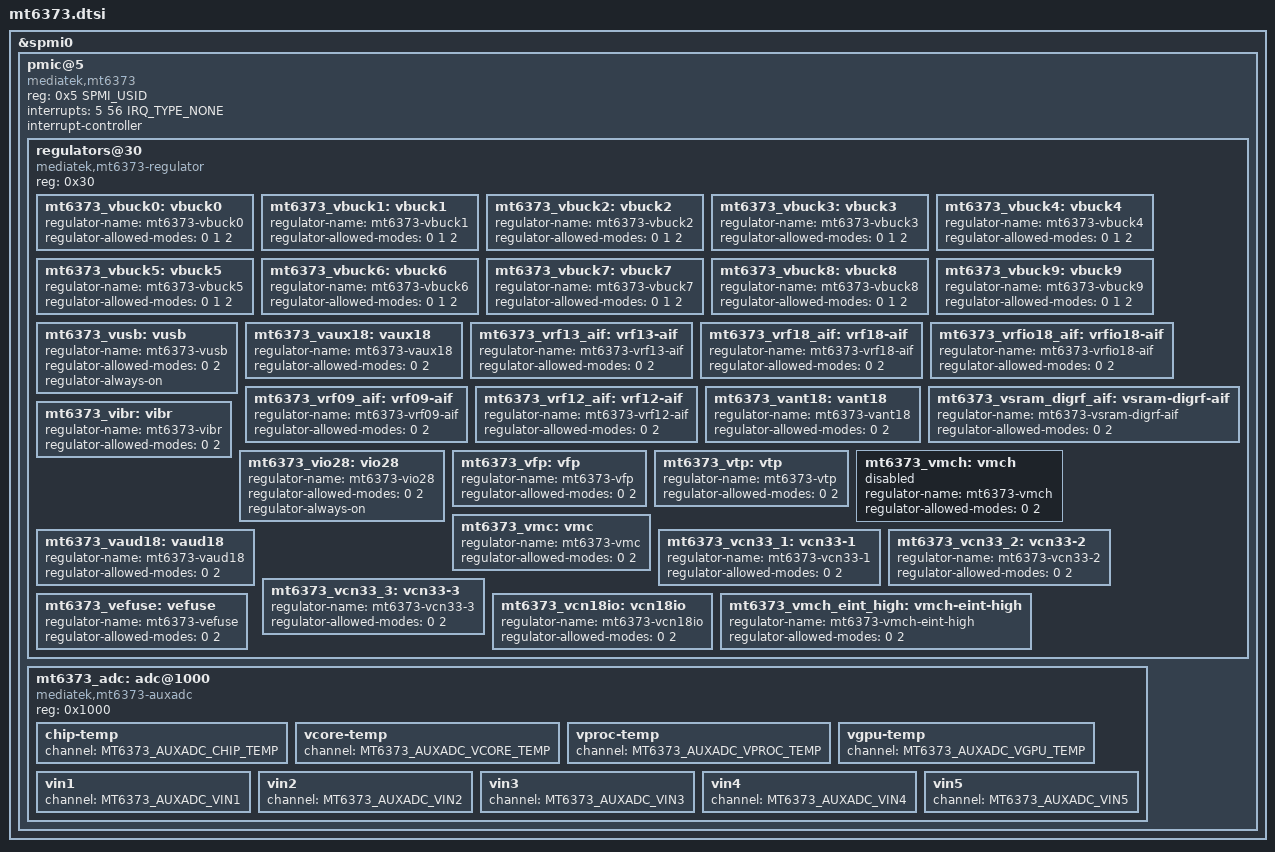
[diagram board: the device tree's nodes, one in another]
// SPDX-License-Identifier: (GPL-2.0 OR MIT)
/*
 * Copyright (c) 2023 MediaTek Inc.
 * Copyright (c) 2025 Collabora Ltd
 *                    AngeloGioacchino Del Regno <angelogioacchino.delregno@collabora.com>
 */
#include <dt-bindings/iio/adc/mediatek,mt6373-auxadc.h>
#include <dt-bindings/interrupt-controller/irq.h>
#include <dt-bindings/spmi/spmi.h>

&spmi0 {
	pmic@5 {
		compatible = "mediatek,mt6373";
		reg = <0x5 SPMI_USID>;
		interrupts = <5 56 IRQ_TYPE_NONE>;
		interrupt-controller;
		#address-cells = <1>;
		#interrupt-cells = <3>;
		#size-cells = <0>;

		regulators@30 {
			compatible = "mediatek,mt6373-regulator";
			reg = <0x30>;

			mt6373_vbuck0: vbuck0 {
				regulator-name = "mt6373-vbuck0";
				regulator-allowed-modes = <0 1 2>;
			};

			mt6373_vbuck1: vbuck1 {
				regulator-name = "mt6373-vbuck1";
				regulator-allowed-modes = <0 1 2>;
			};

			mt6373_vbuck2: vbuck2 {
				regulator-name = "mt6373-vbuck2";
				regulator-allowed-modes = <0 1 2>;
			};

			mt6373_vbuck3: vbuck3 {
				regulator-name = "mt6373-vbuck3";
				regulator-allowed-modes = <0 1 2>;
			};

			mt6373_vbuck4: vbuck4 {
				regulator-name = "mt6373-vbuck4";
				regulator-allowed-modes = <0 1 2>;
			};

			mt6373_vbuck5: vbuck5 {
				regulator-name = "mt6373-vbuck5";
				regulator-allowed-modes = <0 1 2>;
			};

			mt6373_vbuck6: vbuck6 {
				regulator-name = "mt6373-vbuck6";
				regulator-allowed-modes = <0 1 2>;
			};

			mt6373_vbuck7: vbuck7 {
				regulator-name = "mt6373-vbuck7";
				regulator-allowed-modes = <0 1 2>;
			};

			mt6373_vbuck8: vbuck8 {
				regulator-name = "mt6373-vbuck8";
				regulator-allowed-modes = <0 1 2>;
			};

			mt6373_vbuck9: vbuck9 {
				regulator-name = "mt6373-vbuck9";
				regulator-allowed-modes = <0 1 2>;
			};

			mt6373_vusb: vusb {
				regulator-name = "mt6373-vusb";
				regulator-allowed-modes = <0 2>;
				regulator-always-on;
			};

			mt6373_vaux18: vaux18 {
				regulator-name = "mt6373-vaux18";
				regulator-allowed-modes = <0 2>;
			};

			mt6373_vrf13_aif: vrf13-aif {
				regulator-name = "mt6373-vrf13-aif";
				regulator-allowed-modes = <0 2>;
			};

			mt6373_vrf18_aif: vrf18-aif {
				regulator-name = "mt6373-vrf18-aif";
				regulator-allowed-modes = <0 2>;
			};

			mt6373_vrfio18_aif: vrfio18-aif {
				regulator-name = "mt6373-vrfio18-aif";
				regulator-allowed-modes = <0 2>;
			};

			mt6373_vrf09_aif: vrf09-aif {
				regulator-name = "mt6373-vrf09-aif";
				regulator-allowed-modes = <0 2>;
			};

			mt6373_vrf12_aif: vrf12-aif {
				regulator-name = "mt6373-vrf12-aif";
				regulator-allowed-modes = <0 2>;
			};

			mt6373_vant18: vant18 {
				regulator-name = "mt6373-vant18";
				regulator-allowed-modes = <0 2>;
			};

			mt6373_vsram_digrf_aif: vsram-digrf-aif {
				regulator-name = "mt6373-vsram-digrf-aif";
				regulator-allowed-modes = <0 2>;
			};

			mt6373_vibr: vibr {
				regulator-name = "mt6373-vibr";
				regulator-allowed-modes = <0 2>;
			};

			mt6373_vio28: vio28 {
				regulator-name = "mt6373-vio28";
				regulator-allowed-modes = <0 2>;
				regulator-always-on;
			};

			mt6373_vfp: vfp {
				regulator-name = "mt6373-vfp";
				regulator-allowed-modes = <0 2>;
			};

			mt6373_vtp: vtp {
				regulator-name = "mt6373-vtp";
				regulator-allowed-modes = <0 2>;
			};

			mt6373_vmch: vmch {
				regulator-name = "mt6373-vmch";
				regulator-allowed-modes = <0 2>;
				status = "disabled";
			};

			mt6373_vmc: vmc {
				regulator-name = "mt6373-vmc";
				regulator-allowed-modes = <0 2>;
			};

			mt6373_vaud18: vaud18 {
				regulator-name = "mt6373-vaud18";
				regulator-allowed-modes = <0 2>;
			};

			mt6373_vcn33_1: vcn33-1 {
				regulator-name = "mt6373-vcn33-1";
				regulator-allowed-modes = <0 2>;
			};

			mt6373_vcn33_2: vcn33-2 {
				regulator-name = "mt6373-vcn33-2";
				regulator-allowed-modes = <0 2>;
			};

			mt6373_vcn33_3: vcn33-3 {
				regulator-name = "mt6373-vcn33-3";
				regulator-allowed-modes = <0 2>;
			};

			mt6373_vcn18io: vcn18io {
				regulator-name = "mt6373-vcn18io";
				regulator-allowed-modes = <0 2>;
			};

			mt6373_vefuse: vefuse {
				regulator-name = "mt6373-vefuse";
				regulator-allowed-modes = <0 2>;
			};

			mt6373_vmch_eint_high: vmch-eint-high {
				regulator-name = "mt6373-vmch-eint-high";
				regulator-allowed-modes = <0 2>;
			};
		};

		mt6373_adc: adc@1000 {
			compatible = "mediatek,mt6373-auxadc";
			reg = <0x1000>;
			#io-channel-cells = <1>;

			chip-temp {
				channel = <MT6373_AUXADC_CHIP_TEMP>;
			};

			vcore-temp {
				channel = <MT6373_AUXADC_VCORE_TEMP>;
			};

			vproc-temp {
				channel = <MT6373_AUXADC_VPROC_TEMP>;
			};

			vgpu-temp {
				channel = <MT6373_AUXADC_VGPU_TEMP>;
			};

			vin1 {
				channel = <MT6373_AUXADC_VIN1>;
			};

			vin2 {
				channel = <MT6373_AUXADC_VIN2>;
			};

			vin3 {
				channel = <MT6373_AUXADC_VIN3>;
			};

			vin4 {
				channel = <MT6373_AUXADC_VIN4>;
			};

			vin5 {
				channel = <MT6373_AUXADC_VIN5>;
			};
		};
	};
};
